# PIC32CM3204GV00064 register map
Vendor: Microchip Technology; Series: PIC32CMGV00; File version: 0
CPU: CM0+ r0p0, little endian, no MPU, no FPU, VTOR, 2 interrupt priority bits, 25 interrupts
Registers are 8-bit, read-write, reset 0x0 unless marked. A register's access mark holds for its fields unless they carry their own. Offsets are from the block's base; [hi:lo] are bit positions; 'fields as' and 'values as' point back to an identical list.

## SYSCTRL — System Control
Base 0x40000800
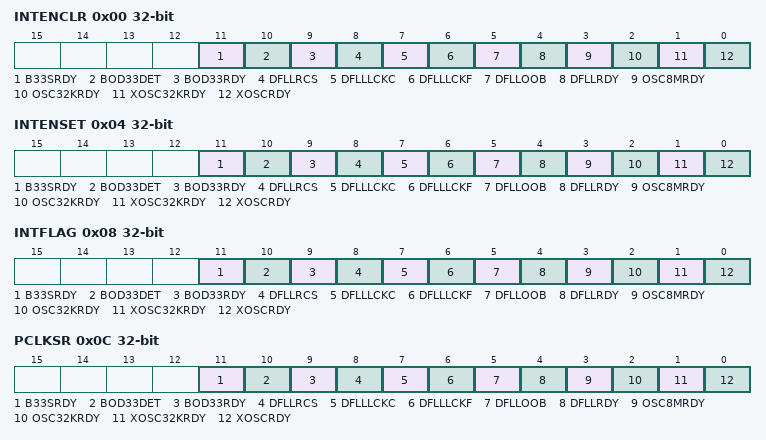
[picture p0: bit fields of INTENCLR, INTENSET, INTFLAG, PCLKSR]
0x00 INTENCLR 32-bit write-1-clears — Interrupt Enable Clear
  [11] B33SRDY — BOD33 Synchronization Ready
  [10] BOD33DET — BOD33 Detection
  [9] BOD33RDY — BOD33 Ready
  [8] DFLLRCS — DFLL Reference Clock Stopped
  [7] DFLLLCKC — DFLL Lock Coarse
  [6] DFLLLCKF — DFLL Lock Fine
  [5] DFLLOOB — DFLL Out Of Bounds
  [4] DFLLRDY — DFLL Ready
  [3] OSC8MRDY — OSC8M Ready
  [2] OSC32KRDY — OSC32K Ready
  [1] XOSC32KRDY — XOSC32K Ready
  [0] XOSCRDY — XOSC Ready
0x04 INTENSET 32-bit write-1-sets — Interrupt Enable Set
  fields as INTENCLR
0x08 INTFLAG 32-bit write-1-clears — Interrupt Flag Status and Clear
  fields as INTENCLR
0x0C PCLKSR 32-bit ro — Power and Clocks Status
  fields as INTENCLR
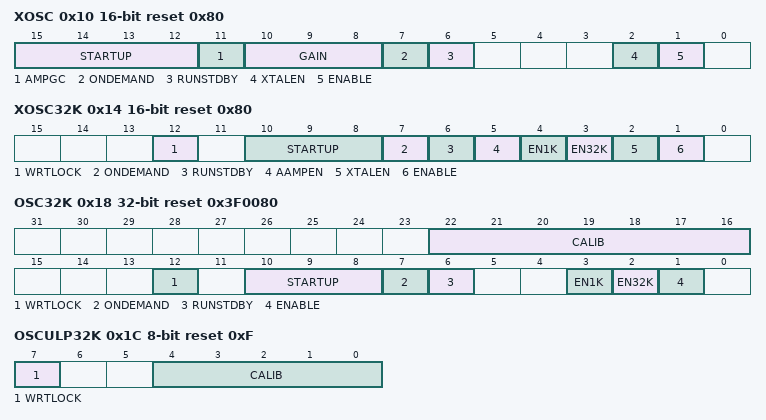
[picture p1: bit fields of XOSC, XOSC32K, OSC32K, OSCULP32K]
0x10 XOSC 16-bit reset 0x80 — External Multipurpose Crystal Oscillator (XOSC) Control
  [15:12] STARTUP — Start-Up Time
    0=CYCLE1 (31 us); 1=CYCLE2 (61 us); 2=CYCLE4 (122 us); 3=CYCLE8 (244 us); 4=CYCLE16 (488 us); 5=CYCLE32 (977 us); 6=CYCLE64 (1953 us); 7=CYCLE128 (3906 us); 8=CYCLE256 (7813 us); 9=CYCLE512 (15625 us); 10=CYCLE1024 (31250 us); 11=CYCLE2048 (62500 us); 12=CYCLE4096 (125000 us); 13=CYCLE8192 (250000 us); 14=CYCLE16384 (500000 us); 15=CYCLE32768 (1000000 us)
  [11] AMPGC — Automatic Amplitude Gain Control
  [10:8] GAIN — Oscillator Gain
    0=2MHz; 1=4MHz; 2=8MHz; 3=16MHz; 4=30MHz
  [7] ONDEMAND — On Demand Control
  [6] RUNSTDBY — Run in Standby
  [2] XTALEN — Crystal Oscillator Enable
  [1] ENABLE — Oscillator Enable
0x14 XOSC32K 16-bit reset 0x80 — 32kHz External Crystal Oscillator (XOSC32K) Control
  [12] WRTLOCK — Write Lock
  [10:8] STARTUP — Oscillator Start-Up Time
    0=CYCLE1 (0.122 ms); 1=CYCLE32 (1.068 ms); 2=CYCLE2048 (62.592 ms); 3=CYCLE4096 (125.092 ms); 4=CYCLE16384 (500.092 ms); 5=CYCLE32768 (1000.092 ms); 6=CYCLE65536 (2000.092 ms); 7=CYCLE131072 (4000.092 ms)
  [7] ONDEMAND — On Demand Control
  [6] RUNSTDBY — Run in Standby
  [5] AAMPEN — Automatic Amplitude Control Enable
  [4] EN1K — 1kHz Output Enable
  [3] EN32K — 32kHz Output Enable
  [2] XTALEN — Crystal Oscillator Enable
  [1] ENABLE — Oscillator Enable
0x18 OSC32K 32-bit reset 0x3F0080 — 32kHz Internal Oscillator (OSC32K) Control
  [22:16] CALIB — Oscillator Calibration
  [12] WRTLOCK — Write Lock
  [10:8] STARTUP — Oscillator Start-Up Time
    0=CYCLE3 (0.092 ms); 1=CYCLE4 (0.122 ms); 2=CYCLE6 (0.183 ms); 3=CYCLE10 (0.305 ms); 4=CYCLE18 (0.549 ms); 5=CYCLE34 (1.038 ms); 6=CYCLE66 (2.014 ms); 7=CYCLE130 (3.967 ms)
  [7] ONDEMAND — On Demand Control
  [6] RUNSTDBY — Run in Standby
  [3] EN1K — 1kHz Output Enable
  [2] EN32K — 32kHz Output Enable
  [1] ENABLE — Oscillator Enable
0x1C OSCULP32K reset 0xF — OSCULP32K Control
  [7] WRTLOCK — Write Lock
  [4:0] CALIB — Calibration Value
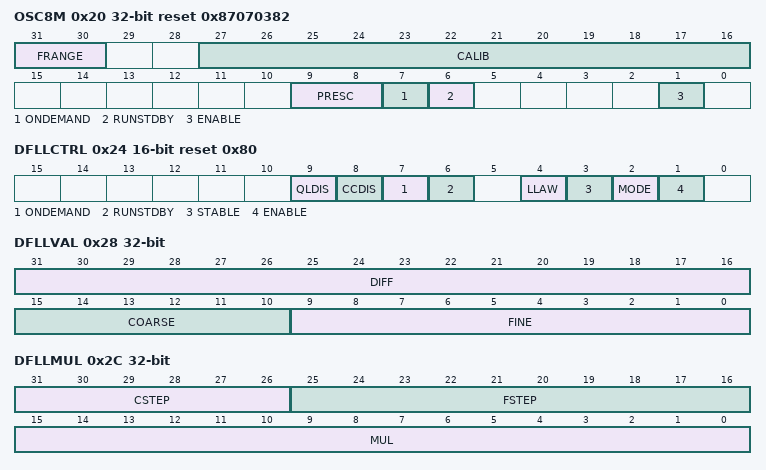
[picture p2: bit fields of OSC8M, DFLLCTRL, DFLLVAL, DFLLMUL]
0x20 OSC8M 32-bit reset 0x87070382 — 8MHz Internal Oscillator (OSC8M) Control
  [31:30] FRANGE — Oscillator Frequency Range
    0=4 to 6MHz; 1=6 to 8MHz; 2=8 to 11MHz; 3=11 to 15MHz
  [27:16] CALIB — Oscillator Calibration
  [9:8] PRESC — Oscillator Prescaler
  [7] ONDEMAND — On Demand Control
  [6] RUNSTDBY — Run in Standby
  [1] ENABLE — Oscillator Enable
0x24 DFLLCTRL 16-bit reset 0x80 — DFLL Config
  [9] QLDIS — Quick Lock Disable
  [8] CCDIS — Chill Cycle Disable
  [7] ONDEMAND — Enable on Demand
  [6] RUNSTDBY — Run during Standby
  [4] LLAW — Lose Lock After Wake
  [3] STABLE — Stable Frequency
  [2] MODE — Mode Selection
  [1] ENABLE
0x28 DFLLVAL 32-bit — DFLL Calibration Value
  [31:16] DIFF — Multiplication Ratio Difference
  [15:10] COARSE — Coarse Calibration Value
  [9:0] FINE — Fine Calibration Value
0x2C DFLLMUL 32-bit — DFLL Multiplier
  [31:26] CSTEP — Maximum Coarse Step Size
  [25:16] FSTEP — Maximum Fine Step Size
  [15:0] MUL — Multiplication Value
0x30 DFLLSYNC — DFLL Synchronization
  [7] READREQ — Read Request Synchronization
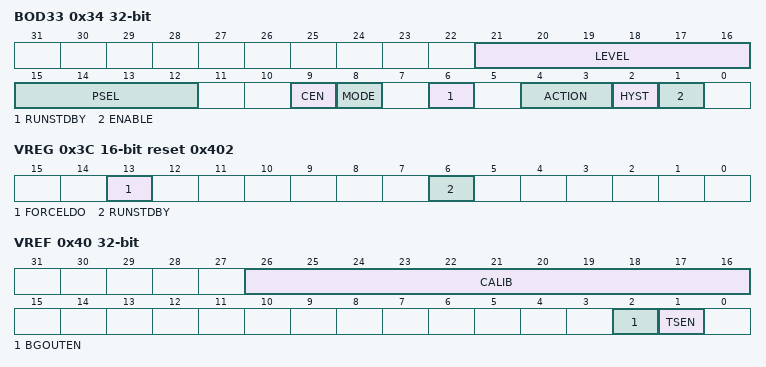
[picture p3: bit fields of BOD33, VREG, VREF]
0x34 BOD33 32-bit — 3.3V Brown-Out Detector (BOD33) Control
  [21:16] LEVEL — Threshold Level
  [15:12] PSEL — Prescaler Select
    0=DIV2 (Divide clock by 2); 1=DIV4 (Divide clock by 4); 2=DIV8 (Divide clock by 8); 3=DIV16 (Divide clock by 16); 4=DIV32 (Divide clock by 32); 5=DIV64 (Divide clock by 64); 6=DIV128 (Divide clock by 128); 7=DIV256 (Divide clock by 256); 8=DIV512 (Divide clock by 512); 9=DIV1024 (Divide clock by 1024); 10=DIV2048 (Divide clock by 2048); 11=DIV4096 (Divide clock by 4096); 12=DIV8192 (Divide clock by 8192); 13=DIV16384 (Divide clock by 16384); 14=DIV32768 (Divide clock by 32768); 15=DIV65536 (Divide clock by 65536)
  [9] CEN — Clock Enable
  [8] MODE — Operation Modes
  [6] RUNSTDBY — Run during Standby
  [4:3] ACTION — Action when Threshold Crossed
    0=NONE (No action); 1=RESET (The BODVDD generates a reset); 2=INT (The BODVDD generates an interrupt)
  [2] HYST — Hysteresis Enable
  [1] ENABLE
0x3C VREG 16-bit reset 0x402 — VREG Control
  [13] FORCELDO — Force LDO Voltage Regulator
  [6] RUNSTDBY — Run during Standby
0x40 VREF 32-bit — VREF Control A
  [26:16] CALIB — Voltage Reference Calibration Value
  [2] BGOUTEN — Bandgap Output Enable
  [1] TSEN — Temperature Sensor Output Enable

## Notices in the file
Copyright (c) 2026 Microchip Technology Inc.
SPDX-License-Identifier: Apache-2.0
Licensed under the Apache License, Version 2.0 (the "License");
you may not use this file except in compliance with the License.
You may obtain a copy of the License at
http://www.apache.org/licenses/LICENSE-2.0
Unless required by applicable law or agreed to in writing, software
distributed under the License is distributed on an "AS IS" BASIS,
WITHOUT WARRANTIES OR CONDITIONS OF ANY KIND, either express or implied.
See the License for the specific language governing permissions and
limitations under the License.
